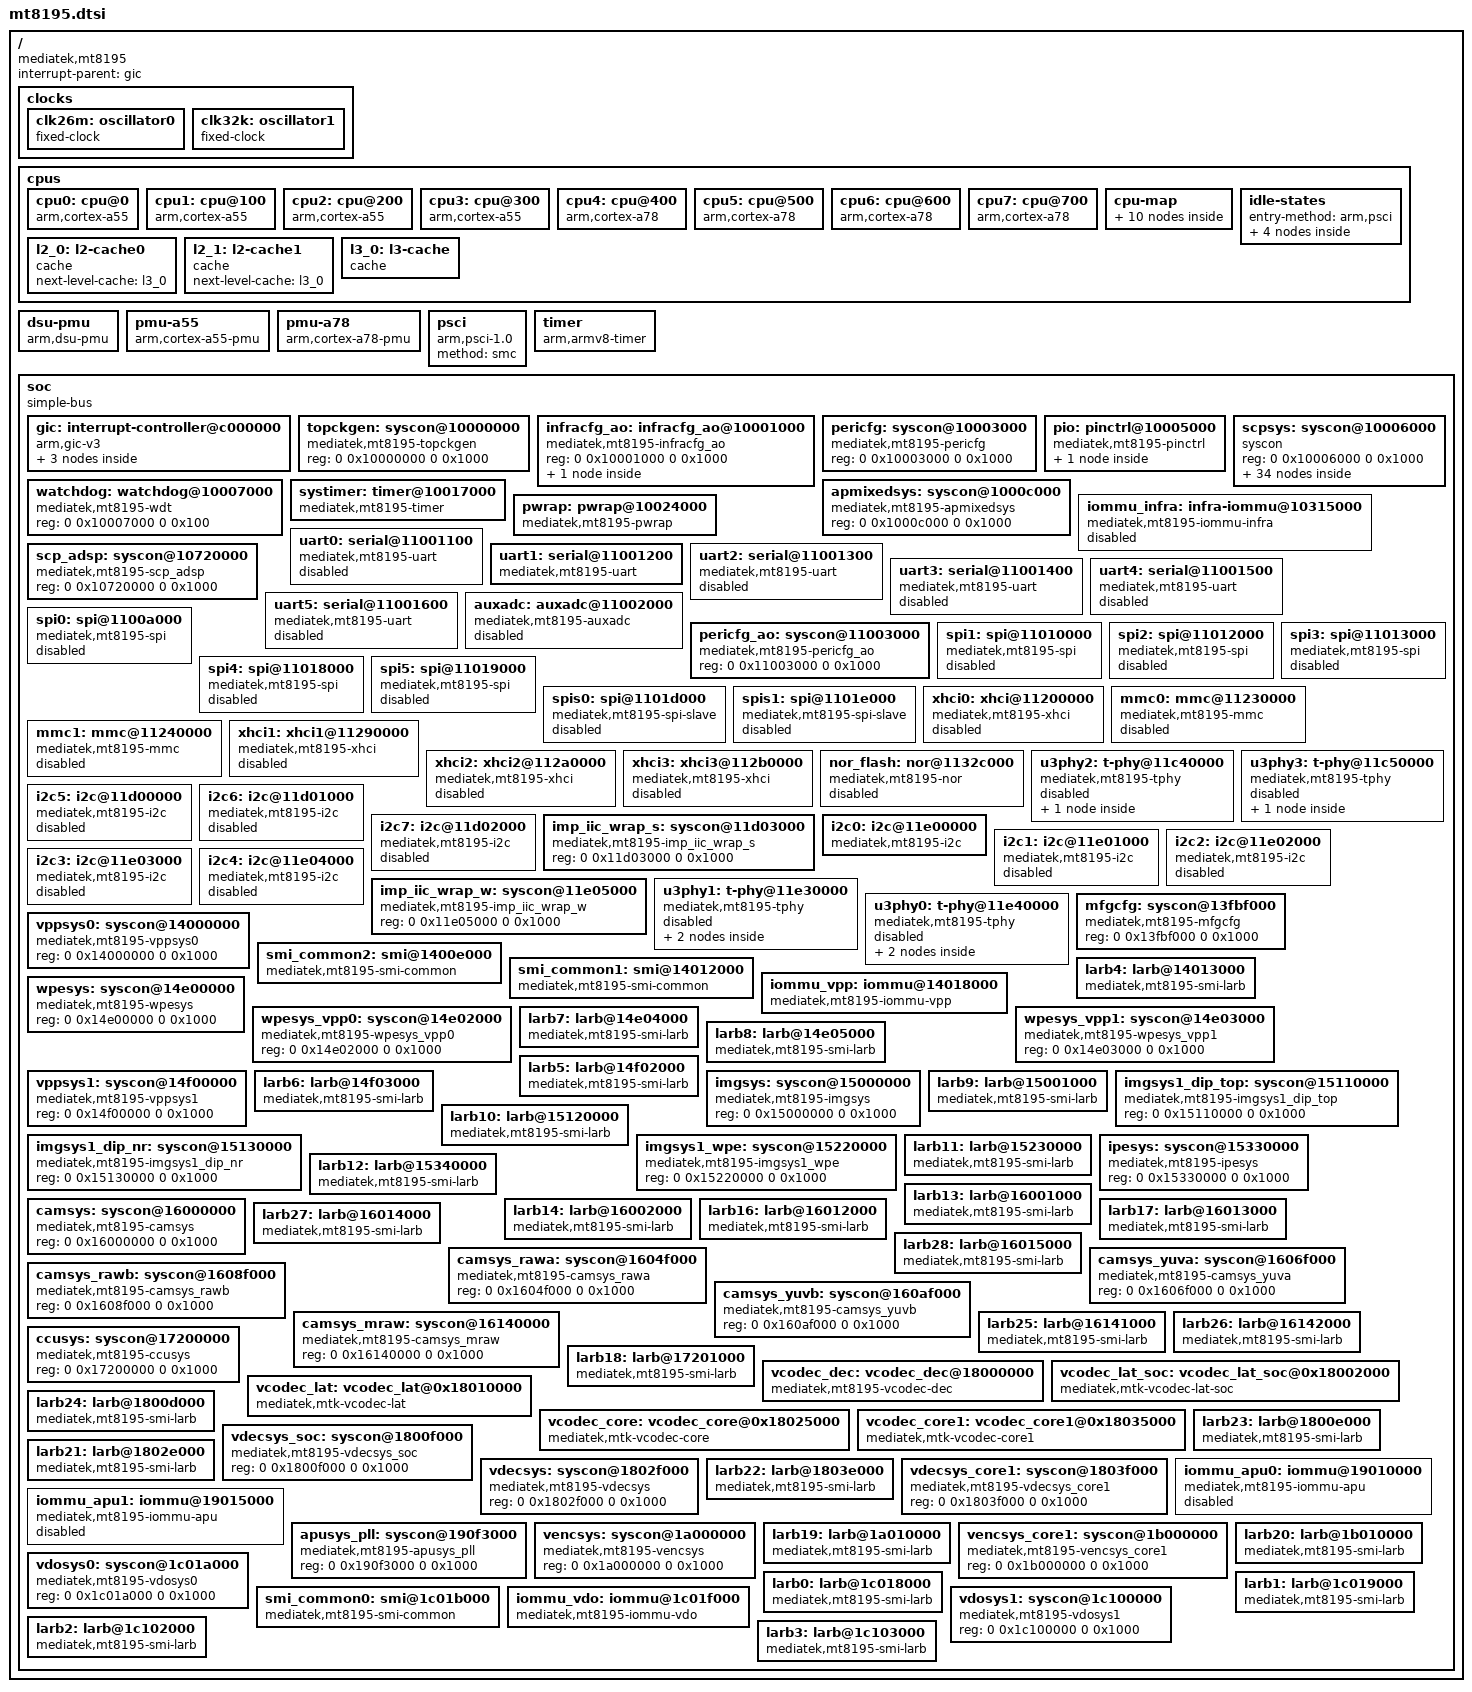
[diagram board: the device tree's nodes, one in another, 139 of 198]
// SPDX-License-Identifier: (GPL-2.0 OR MIT)
/*
 * Copyright (c) 2021 MediaTek Inc.
 * Author: Seiya Wang <seiya.wang@mediatek.com>
 */

/dts-v1/;

#include <dt-bindings/clock/mt8195-clk.h>
#include <dt-bindings/interrupt-controller/arm-gic.h>
#include <dt-bindings/interrupt-controller/irq.h>
#include <dt-bindings/memory/mt8195-memory-port.h>
#include <dt-bindings/phy/phy.h>
#include <dt-bindings/pinctrl/mt8195-pinfunc.h>
#include <dt-bindings/power/mt8195-power.h>
#include <dt-bindings/reset/ti-syscon.h>

/ {
	compatible = "mediatek,mt8195";
	interrupt-parent = <&gic>;
	#address-cells = <2>;
	#size-cells = <2>;

	clocks {
		clk26m: oscillator0 {
			compatible = "fixed-clock";
			#clock-cells = <0>;
			clock-frequency = <26000000>;
			clock-output-names = "clk26m";
		};

		clk32k: oscillator1 {
			compatible = "fixed-clock";
			#clock-cells = <0>;
			clock-frequency = <32768>;
			clock-output-names = "clk32k";
		};
	};

	cpus {
		#address-cells = <1>;
		#size-cells = <0>;

		cpu0: cpu@0 {
			device_type = "cpu";
			compatible = "arm,cortex-a55", "arm,armv8";
			reg = <0x000>;
			enable-method = "psci";
			clock-frequency = <1701000000>;
			capacity-dmips-mhz = <578>;
			cpu-idle-states = <&cpuoff_l &clusteroff_l>;
			next-level-cache = <&l2_0>;
			#cooling-cells = <2>;
		};

		cpu1: cpu@100 {
			device_type = "cpu";
			compatible = "arm,cortex-a55", "arm,armv8";
			reg = <0x100>;
			enable-method = "psci";
			clock-frequency = <1701000000>;
			capacity-dmips-mhz = <578>;
			cpu-idle-states = <&cpuoff_l &clusteroff_l>;
			next-level-cache = <&l2_0>;
			#cooling-cells = <2>;
		};

		cpu2: cpu@200 {
			device_type = "cpu";
			compatible = "arm,cortex-a55", "arm,armv8";
			reg = <0x200>;
			enable-method = "psci";
			clock-frequency = <1701000000>;
			capacity-dmips-mhz = <578>;
			cpu-idle-states = <&cpuoff_l &clusteroff_l>;
			next-level-cache = <&l2_0>;
			#cooling-cells = <2>;
		};

		cpu3: cpu@300 {
			device_type = "cpu";
			compatible = "arm,cortex-a55", "arm,armv8";
			reg = <0x300>;
			enable-method = "psci";
			clock-frequency = <1701000000>;
			capacity-dmips-mhz = <578>;
			cpu-idle-states = <&cpuoff_l &clusteroff_l>;
			next-level-cache = <&l2_0>;
			#cooling-cells = <2>;
		};

		cpu4: cpu@400 {
			device_type = "cpu";
			compatible = "arm,cortex-a78", "arm,armv8";
			reg = <0x400>;
			enable-method = "psci";
			clock-frequency = <2171000000>;
			capacity-dmips-mhz = <1024>;
			cpu-idle-states = <&cpuoff_b &clusteroff_b>;
			next-level-cache = <&l2_1>;
			#cooling-cells = <2>;
		};

		cpu5: cpu@500 {
			device_type = "cpu";
			compatible = "arm,cortex-a78", "arm,armv8";
			reg = <0x500>;
			enable-method = "psci";
			clock-frequency = <2171000000>;
			capacity-dmips-mhz = <1024>;
			cpu-idle-states = <&cpuoff_b &clusteroff_b>;
			next-level-cache = <&l2_1>;
			#cooling-cells = <2>;
		};

		cpu6: cpu@600 {
			device_type = "cpu";
			compatible = "arm,cortex-a78", "arm,armv8";
			reg = <0x600>;
			enable-method = "psci";
			clock-frequency = <2171000000>;
			capacity-dmips-mhz = <1024>;
			cpu-idle-states = <&cpuoff_b &clusteroff_b>;
			next-level-cache = <&l2_1>;
			#cooling-cells = <2>;
		};

		cpu7: cpu@700 {
			device_type = "cpu";
			compatible = "arm,cortex-a78", "arm,armv8";
			reg = <0x700>;
			enable-method = "psci";
			clock-frequency = <2171000000>;
			capacity-dmips-mhz = <1024>;
			cpu-idle-states = <&cpuoff_b &clusteroff_b>;
			next-level-cache = <&l2_1>;
			#cooling-cells = <2>;
		};

		cpu-map {
			cluster0 {
				core0 {
					cpu = <&cpu0>;
				};
				core1 {
					cpu = <&cpu1>;
				};
				core2 {
					cpu = <&cpu2>;
				};
				core3 {
					cpu = <&cpu3>;
				};
			};
			cluster1 {
				core0 {
					cpu = <&cpu4>;
				};
				core1 {
					cpu = <&cpu5>;
				};
				core2 {
					cpu = <&cpu6>;
				};
				core3 {
					cpu = <&cpu7>;
				};
			};
		};

		idle-states {
			entry-method = "arm,psci";
			cpuoff_l: cpuoff_l {
				compatible = "arm,idle-state";
				arm,psci-suspend-param = <0x00010001>;
				local-timer-stop;
				entry-latency-us = <50>;
				exit-latency-us = <95>;
				min-residency-us = <580>;
			};
			cpuoff_b: cpuoff_b {
				compatible = "arm,idle-state";
				arm,psci-suspend-param = <0x00010001>;
				local-timer-stop;
				entry-latency-us = <45>;
				exit-latency-us = <140>;
				min-residency-us = <740>;
			};
			clusteroff_l: clusteroff_l {
				compatible = "arm,idle-state";
				arm,psci-suspend-param = <0x01010002>;
				local-timer-stop;
				entry-latency-us = <55>;
				exit-latency-us = <155>;
				min-residency-us = <840>;
			};
			clusteroff_b: clusteroff_b {
				compatible = "arm,idle-state";
				arm,psci-suspend-param = <0x01010002>;
				local-timer-stop;
				entry-latency-us = <50>;
				exit-latency-us = <200>;
				min-residency-us = <1000>;
			};
		};

		l2_0: l2-cache0 {
			compatible = "cache";
			next-level-cache = <&l3_0>;
		};

		l2_1: l2-cache1 {
			compatible = "cache";
			next-level-cache = <&l3_0>;
		};

		l3_0: l3-cache {
			compatible = "cache";
		};
	};

	dsu-pmu {
		compatible = "arm,dsu-pmu";
		interrupts = <GIC_SPI 18 IRQ_TYPE_LEVEL_HIGH 0>;
		cpus = <&cpu0>, <&cpu1>, <&cpu2>, <&cpu3>,
		       <&cpu4>, <&cpu5>, <&cpu6>, <&cpu7>;
	};

	pmu-a55 {
		compatible = "arm,cortex-a55-pmu";
		interrupt-parent = <&gic>;
		interrupts = <GIC_PPI 7 IRQ_TYPE_LEVEL_HIGH &ppi_cluster0>;
	};

	pmu-a78 {
		compatible = "arm,cortex-a78-pmu";
		interrupt-parent = <&gic>;
		interrupts = <GIC_PPI 7 IRQ_TYPE_LEVEL_HIGH &ppi_cluster1>;
	};

	psci {
		compatible = "arm,psci-1.0";
		method = "smc";
	};

	timer: timer {
		compatible = "arm,armv8-timer";
		interrupt-parent = <&gic>;
		interrupts = <GIC_PPI 13 IRQ_TYPE_LEVEL_HIGH 0>,
			     <GIC_PPI 14 IRQ_TYPE_LEVEL_HIGH 0>,
			     <GIC_PPI 11 IRQ_TYPE_LEVEL_HIGH 0>,
			     <GIC_PPI 10 IRQ_TYPE_LEVEL_HIGH 0>;
		clock-frequency = <13000000>;
	};

	soc {
		#address-cells = <2>;
		#size-cells = <2>;
		compatible = "simple-bus";
		ranges;

		gic: interrupt-controller@c000000 {
			compatible = "arm,gic-v3";
			#interrupt-cells = <4>;
			#redistributor-regions = <1>;
			interrupt-parent = <&gic>;
			interrupt-controller;
			reg = <0 0x0c000000 0 0x40000>,
			      <0 0x0c040000 0 0x200000>;
			interrupts = <GIC_PPI 9 IRQ_TYPE_LEVEL_HIGH 0>;

			ppi-partitions {
				ppi_cluster0: interrupt-partition-0 {
					affinity = <&cpu0 &cpu1 &cpu2 &cpu3>;
				};
				ppi_cluster1: interrupt-partition-1 {
					affinity = <&cpu4 &cpu5 &cpu6 &cpu7>;
				};
			};
		};

		topckgen: syscon@10000000 {
			compatible = "mediatek,mt8195-topckgen", "syscon";
			reg = <0 0x10000000 0 0x1000>;
			#clock-cells = <1>;
		};

		infracfg_ao: infracfg_ao@10001000 {
			compatible = "mediatek,mt8195-infracfg_ao", "syscon", "simple-mfd";
			reg = <0 0x10001000 0 0x1000>;
			#clock-cells = <1>;
			infracfg_rst: reset-controller {
				compatible = "ti,syscon-reset";
				#reset-cells = <1>;
				ti,reset-bits = <
					0x140 18 0x144 18 0 0 (ASSERT_SET | DEASSERT_SET | STATUS_NONE)
					0x120 1 0x124 1 0 0   (ASSERT_SET | DEASSERT_SET | STATUS_NONE)
					0x730 1 0x734 1 0 0   (ASSERT_SET | DEASSERT_SET | STATUS_NONE)
					0x150 5 0x154 5 0 0   (ASSERT_SET | DEASSERT_SET | STATUS_NONE)
				>;
			};
		};

		pericfg: syscon@10003000 {
			compatible = "mediatek,mt8195-pericfg", "syscon";
			reg = <0 0x10003000 0 0x1000>;
			#clock-cells = <1>;
		};

		pio: pinctrl@10005000 {
			compatible = "mediatek,mt8195-pinctrl";
			reg = <0 0x10005000 0 0x1000>,
			      <0 0x11d10000 0 0x1000>,
			      <0 0x11d30000 0 0x1000>,
			      <0 0x11d40000 0 0x1000>,
			      <0 0x11e20000 0 0x1000>,
			      <0 0x11eb0000 0 0x1000>,
			      <0 0x11f40000 0 0x1000>,
			      <0 0x1000b000 0 0x1000>;
			reg-names = "iocfg0", "iocfg_bm", "iocfg_bl",
				    "iocfg_br", "iocfg_lm", "iocfg_rb",
				    "iocfg_tl", "eint";
			gpio-controller;
			#gpio-cells = <2>;
			gpio-ranges = <&pio 0 0 144>;
			interrupt-controller;
			interrupts = <GIC_SPI 212 IRQ_TYPE_LEVEL_HIGH 0>;
			#interrupt-cells = <2>;

			pmif_pin: pmif_default_pin {
				pinmux = <PINMUX_GPIO36__FUNC_RTC32K_CK>,
					 <PINMUX_GPIO40__FUNC_PWRAP_SPI0_CSN>,
					 <PINMUX_GPIO41__FUNC_PWRAP_SPI0_CK>,
					 <PINMUX_GPIO42__FUNC_PWRAP_SPI0_MO>,
					 <PINMUX_GPIO43__FUNC_PWRAP_SPI0_MI>,
					 <PINMUX_GPIO44__FUNC_SPMI_M_SCL>,
					 <PINMUX_GPIO45__FUNC_SPMI_M_SDA>;
			};
		};

		scpsys: syscon@10006000 {
			compatible = "syscon", "simple-mfd";
			reg = <0 0x10006000 0 0x1000>;
			#power-domain-cells = <1>;

			/* System Power Manager */
			spm: power-controller {
				compatible = "mediatek,mt8195-power-controller";
				#address-cells = <1>;
				#size-cells = <0>;
				#power-domain-cells = <1>;

				/* power domain of the SoC */
				power-domain@MT8195_POWER_DOMAIN_PCIE_MAC_P0 {
					reg = <MT8195_POWER_DOMAIN_PCIE_MAC_P0>;
					mediatek,infracfg = <&infracfg_ao>;
					#power-domain-cells = <0>;
				};

				power-domain@MT8195_POWER_DOMAIN_PCIE_MAC_P1 {
					reg = <MT8195_POWER_DOMAIN_PCIE_MAC_P1>;
					mediatek,infracfg = <&infracfg_ao>;
					#power-domain-cells = <0>;
				};

				power-domain@MT8195_POWER_DOMAIN_PCIE_PHY {
					reg = <MT8195_POWER_DOMAIN_PCIE_PHY>;
					#power-domain-cells = <0>;
				};

				power-domain@MT8195_POWER_DOMAIN_SSUSB_PCIE_PHY {
					reg = <MT8195_POWER_DOMAIN_SSUSB_PCIE_PHY>;
					#power-domain-cells = <0>;
				};

				power-domain@MT8195_POWER_DOMAIN_CSI_RX_TOP {
					reg = <MT8195_POWER_DOMAIN_CSI_RX_TOP>;
					clocks = <&topckgen CLK_TOP_SENINF>,
						 <&topckgen CLK_TOP_SENINF2>;
					clock-names = "csi_rx_top", "csi_rx_top1";
					#power-domain-cells = <0>;
				};

				power-domain@MT8195_POWER_DOMAIN_ETHER {
					reg = <MT8195_POWER_DOMAIN_ETHER>;
					clocks = <&pericfg_ao CLK_PERI_AO_ETHERNET_MAC>;
					clock-names = "ether";
					#power-domain-cells = <0>;
				};
#if 0
				power-domain@MT8195_POWER_DOMAIN_ADSP {
					reg = <MT8195_POWER_DOMAIN_ADSP>;
					clocks = <&topckgen CLK_TOP_ADSP>,
						 <&topckgen CLK_TOP_AUDIO_LOCAL_BUS>;
					clock-names = "adsp", "bus";
					#address-cells = <1>;
					#size-cells = <0>;
					#power-domain-cells = <1>;

					power-domain@MT8195_POWER_DOMAIN_AUDIO {
						reg = <MT8195_POWER_DOMAIN_AUDIO>;
						clocks = <&topckgen CLK_TOP_A1SYS_HP>,
							 <&topckgen CLK_TOP_AUD_INTBUS>,
							 <&topckgen CLK_TOP_AUDIO_LOCAL_BUS>,
							 <&infracfg_ao CLK_INFRA_AO_AUDIO_26M_B>;
						clock-names = "audio", "int_bus", "bus", "ao";
						mediatek,infracfg = <&infracfg_ao>;
						#power-domain-cells = <0>;
					};
				};

				/*power-domain@MT8195_POWER_DOMAIN_AUDIO_ASRC {
					reg = <MT8195_POWER_DOMAIN_AUDIO_ASRC>;
					clocks = <&topckgen CLK_TOP_AUDIO_LOCAL_BUS_SEL>,
						 <&topckgen CLK_TOP_ASM_L_SEL>,
						 <&infracfg_ao CLK_INFRA_AO_AUDIO_26M_B>;
					clock-names = "audio_asrc", "audio_asrc1", "audio_asrc2";
					mediatek,infracfg = <&infracfg_ao>;
					#power-domain-cells = <0>;
				};*/

				/*power-domain@MT8195_POWER_DOMAIN_NNA {
					reg = <MT8195_POWER_DOMAIN_NNA>;
					clocks = <&topckgen CLK_TOP_NNA0_SEL>;
					clock-names = "nna";
					mediatek,infracfg = <&infracfg_ao>;
					#address-cells = <1>;
					#size-cells = <0>;
					#power-domain-cells = <1>;

					power-domain@MT8195_POWER_DOMAIN_NNA0 {
						reg = <MT8195_POWER_DOMAIN_NNA0>;
						mediatek,infracfg = <&infracfg_ao>;
						#power-domain-cells = <0>;
					};

					power-domain@MT8195_POWER_DOMAIN_NNA1 {
						reg = <MT8195_POWER_DOMAIN_NNA1>;
						mediatek,infracfg = <&infracfg_ao>;
						#power-domain-cells = <0>;
					};
				};*/
#endif
				power-domain@MT8195_POWER_DOMAIN_MFG0 {
					reg = <MT8195_POWER_DOMAIN_MFG0>;
					#address-cells = <1>;
					#size-cells = <0>;
					#power-domain-cells = <1>;

					power-domain@MT8195_POWER_DOMAIN_MFG1 {
						reg = <MT8195_POWER_DOMAIN_MFG1>;
						clocks = <&apmixedsys CLK_APMIXED_MFGPLL>;
						clock-names = "mfg";
						mediatek,infracfg = <&infracfg_ao>;
						#address-cells = <1>;
						#size-cells = <0>;
						#power-domain-cells = <1>;

						power-domain@MT8195_POWER_DOMAIN_MFG2 {
							reg = <MT8195_POWER_DOMAIN_MFG2>;
							#power-domain-cells = <0>;
						};

						power-domain@MT8195_POWER_DOMAIN_MFG3 {
							reg = <MT8195_POWER_DOMAIN_MFG3>;
							#power-domain-cells = <0>;
						};

						power-domain@MT8195_POWER_DOMAIN_MFG4 {
							reg = <MT8195_POWER_DOMAIN_MFG4>;
							#power-domain-cells = <0>;
						};

						power-domain@MT8195_POWER_DOMAIN_MFG5 {
							reg = <MT8195_POWER_DOMAIN_MFG5>;
							#power-domain-cells = <0>;
						};

						power-domain@MT8195_POWER_DOMAIN_MFG6 {
							reg = <MT8195_POWER_DOMAIN_MFG6>;
							#power-domain-cells = <0>;
						};
					};
				};

				power-domain@MT8195_POWER_DOMAIN_VPPSYS0 {
					reg = <MT8195_POWER_DOMAIN_VPPSYS0>;
					clocks = <&topckgen CLK_TOP_VPP>,
						 <&topckgen CLK_TOP_CAM>,
						 <&topckgen CLK_TOP_CCU>,
						 <&topckgen CLK_TOP_IMG>,
						 <&topckgen CLK_TOP_VENC>,
						 <&topckgen CLK_TOP_VDEC>,
						 <&topckgen CLK_TOP_WPE_VPP>,
						 <&topckgen CLK_TOP_CFG_VPP0>,
						 <&vppsys0 CLK_VPP0_SMI_COMMON>,
						 <&vppsys0 CLK_VPP0_GALS_VDO0_LARB0>,
						 <&vppsys0 CLK_VPP0_GALS_VDO0_LARB1>,
						 <&vppsys0 CLK_VPP0_GALS_VENCSYS>,
						 <&vppsys0 CLK_VPP0_GALS_VENCSYS_CORE1>,
						 <&vppsys0 CLK_VPP0_GALS_INFRA>,
						 <&vppsys0 CLK_VPP0_GALS_CAMSYS>,
						 <&vppsys0 CLK_VPP0_GALS_VPP1_LARB5>,
						 <&vppsys0 CLK_VPP0_GALS_VPP1_LARB6>,
						 <&vppsys0 CLK_VPP0_SMI_REORDER>,
						 <&vppsys0 CLK_VPP0_SMI_IOMMU>,
						 <&vppsys0 CLK_VPP0_GALS_IMGSYS_CAMSYS>,
						 <&vppsys0 CLK_VPP0_GALS_EMI0_EMI1>,
						 <&vppsys0 CLK_VPP0_SMI_SUB_COMMON_REORDER>,
						 <&vppsys0 CLK_VPP0_SMI_RSI>,
						 <&vppsys0 CLK_VPP0_SMI_COMMON_LARB4>,
						 <&vppsys0 CLK_VPP0_GALS_VDEC_VDEC_CORE1>,
						 <&vppsys0 CLK_VPP0_GALS_VPP1_WPE>,
						 <&vppsys0 CLK_VPP0_GALS_VDO0_VDO1_VENCSYS_CORE1>;
					clock-names = "vppsys", "vppsys1", "vppsys2", "vppsys3",
						      "vppsys4", "vppsys5", "vppsys6", "vppsys7",
						      "vppsys0-0", "vppsys0-1", "vppsys0-2", "vppsys0-3",
						      "vppsys0-4", "vppsys0-5", "vppsys0-6", "vppsys0-7",
						      "vppsys0-8", "vppsys0-9", "vppsys0-10", "vppsys0-11",
						      "vppsys0-12", "vppsys0-13", "vppsys0-14",
						      "vppsys0-15", "vppsys0-16", "vppsys0-17",
						      "vppsys0-18";
					mediatek,infracfg = <&infracfg_ao>;
					#address-cells = <1>;
					#size-cells = <0>;
					#power-domain-cells = <1>;

					power-domain@MT8195_POWER_DOMAIN_VDEC1 {
						reg = <MT8195_POWER_DOMAIN_VDEC1>;
						clocks = <&vdecsys CLK_VDEC_LARB1>;
						clock-names = "vdec1-0";
						mediatek,infracfg = <&infracfg_ao>;
						#power-domain-cells = <0>;
					};

					power-domain@MT8195_POWER_DOMAIN_VENC_CORE1 {
						reg = <MT8195_POWER_DOMAIN_VENC_CORE1>;
						mediatek,infracfg = <&infracfg_ao>;
						#power-domain-cells = <0>;
					};

					power-domain@MT8195_POWER_DOMAIN_VDOSYS0 {
						reg = <MT8195_POWER_DOMAIN_VDOSYS0>;
						clocks = <&topckgen CLK_TOP_CFG_VDO0>,
							 <&vdosys0 CLK_VDO0_SMI_GALS>,
							 <&vdosys0 CLK_VDO0_SMI_COMMON>,
							 <&vdosys0 CLK_VDO0_SMI_EMI>,
							 <&vdosys0 CLK_VDO0_SMI_IOMMU>,
							 <&vdosys0 CLK_VDO0_SMI_LARB>,
							 <&vdosys0 CLK_VDO0_SMI_RSI>;
						clock-names = "vdosys0", "vdosys0-0", "vdosys0-1",
							      "vdosys0-2", "vdosys0-3",
							      "vdosys0-4", "vdosys0-5";
						mediatek,infracfg = <&infracfg_ao>;
						#address-cells = <1>;
						#size-cells = <0>;
						#power-domain-cells = <1>;

						power-domain@MT8195_POWER_DOMAIN_VPPSYS1 {
							reg = <MT8195_POWER_DOMAIN_VPPSYS1>;
							clocks = <&topckgen CLK_TOP_CFG_VPP1>,
								 <&vppsys1 CLK_VPP1_VPPSYS1_GALS>,
								 <&vppsys1 CLK_VPP1_VPPSYS1_LARB>;
							clock-names = "vppsys1", "vppsys1-0",
								      "vppsys1-1";
							mediatek,infracfg = <&infracfg_ao>;
							#power-domain-cells = <0>;
						};

						power-domain@MT8195_POWER_DOMAIN_WPESYS {
							reg = <MT8195_POWER_DOMAIN_WPESYS>;
							clocks = <&wpesys CLK_WPE_SMI_LARB7>,
								 <&wpesys CLK_WPE_SMI_LARB8>,
								 <&wpesys CLK_WPE_SMI_LARB7_P>,
								 <&wpesys CLK_WPE_SMI_LARB8_P>;
							clock-names = "wepsys-0", "wepsys-1", "wepsys-2",
								      "wepsys-3";
							mediatek,infracfg = <&infracfg_ao>;
							#power-domain-cells = <0>;
						};

						power-domain@MT8195_POWER_DOMAIN_VDEC0 {
							reg = <MT8195_POWER_DOMAIN_VDEC0>;
							clocks = <&vdecsys_soc CLK_VDEC_SOC_LARB1>;
							clock-names = "vdec0-0";
							mediatek,infracfg = <&infracfg_ao>;
							#power-domain-cells = <0>;
						};

						power-domain@MT8195_POWER_DOMAIN_VDEC2 {
							reg = <MT8195_POWER_DOMAIN_VDEC2>;
							clocks = <&vdecsys_core1 CLK_VDEC_CORE1_LARB1>;
							clock-names = "vdec2-0";
							mediatek,infracfg = <&infracfg_ao>;
							#power-domain-cells = <0>;
						};

						power-domain@MT8195_POWER_DOMAIN_VENC {
							reg = <MT8195_POWER_DOMAIN_VENC>;
							mediatek,infracfg = <&infracfg_ao>;
							#power-domain-cells = <0>;
						};

						power-domain@MT8195_POWER_DOMAIN_VDOSYS1 {
							reg = <MT8195_POWER_DOMAIN_VDOSYS1>;
							clocks = <&topckgen CLK_TOP_CFG_VDO1>,
								 <&vdosys1 CLK_VDO1_SMI_LARB2>,
								 <&vdosys1 CLK_VDO1_SMI_LARB3>,
								 <&vdosys1 CLK_VDO1_GALS>;
							clock-names = "vdosys1", "vdosys1-0",
								      "vdosys1-1", "vdosys1-2";
							mediatek,infracfg = <&infracfg_ao>;
							#address-cells = <1>;
							#size-cells = <0>;
							#power-domain-cells = <1>;

							power-domain@MT8195_POWER_DOMAIN_DP_TX {
								reg = <MT8195_POWER_DOMAIN_DP_TX>;
								mediatek,infracfg = <&infracfg_ao>;
								#power-domain-cells = <0>;
							};

							power-domain@MT8195_POWER_DOMAIN_EPD_TX {
								reg = <MT8195_POWER_DOMAIN_EPD_TX>;
								mediatek,infracfg = <&infracfg_ao>;
								#power-domain-cells = <0>;
							};

							power-domain@MT8195_POWER_DOMAIN_HDMI_TX {
								reg = <MT8195_POWER_DOMAIN_HDMI_TX>;
								clocks = <&topckgen CLK_TOP_HDMI_APB>;
								clock-names = "hdmi_tx";
								#power-domain-cells = <0>;
							};
						};

						power-domain@MT8195_POWER_DOMAIN_IMG {
							reg = <MT8195_POWER_DOMAIN_IMG>;
							clocks = <&imgsys CLK_IMG_LARB9>,
								 <&imgsys CLK_IMG_GALS>;
							clock-names = "img-0", "img-1";
							mediatek,infracfg = <&infracfg_ao>;
							#address-cells = <1>;
							#size-cells = <0>;
							#power-domain-cells = <1>;

							power-domain@MT8195_POWER_DOMAIN_DIP {
								reg = <MT8195_POWER_DOMAIN_DIP>;
								#power-domain-cells = <0>;
							};

							power-domain@MT8195_POWER_DOMAIN_IPE {
								reg = <MT8195_POWER_DOMAIN_IPE>;
								clocks = <&topckgen CLK_TOP_IPE>,
									 <&imgsys CLK_IMG_IPE>,
									 <&ipesys CLK_IPE_SMI_LARB12>;
								clock-names = "ipe", "ipe-0", "ipe-1";
								mediatek,infracfg = <&infracfg_ao>;
								#power-domain-cells = <0>;
							};
						};

						power-domain@MT8195_POWER_DOMAIN_CAM {
							reg = <MT8195_POWER_DOMAIN_CAM>;
							clocks = <&camsys CLK_CAM_LARB13>,
								 <&camsys CLK_CAM_LARB14>,
								 <&camsys CLK_CAM_CAM2MM0_GALS>,
								 <&camsys CLK_CAM_CAM2MM1_GALS>,
								 <&camsys CLK_CAM_CAM2SYS_GALS>;
							clock-names = "cam-0", "cam-1", "cam-2", "cam-3",
								      "cam-4";
							mediatek,infracfg = <&infracfg_ao>;
							#address-cells = <1>;
							#size-cells = <0>;
							#power-domain-cells = <1>;

							power-domain@MT8195_POWER_DOMAIN_CAM_RAWA {
								reg = <MT8195_POWER_DOMAIN_CAM_RAWA>;
								#power-domain-cells = <0>;
							};

							power-domain@MT8195_POWER_DOMAIN_CAM_RAWB {
								reg = <MT8195_POWER_DOMAIN_CAM_RAWB>;
								#power-domain-cells = <0>;
							};

							power-domain@MT8195_POWER_DOMAIN_CAM_MRAW {
								reg = <MT8195_POWER_DOMAIN_CAM_MRAW>;
								#power-domain-cells = <0>;
							};
						};
					};
				};
			};
		};

		watchdog: watchdog@10007000 {
			compatible = "mediatek,mt8195-wdt",
				     "mediatek,mt6589-wdt";
			reg = <0 0x10007000 0 0x100>;
		};

		apmixedsys: syscon@1000c000 {
			compatible = "mediatek,mt8195-apmixedsys", "syscon";
			reg = <0 0x1000c000 0 0x1000>;
			#clock-cells = <1>;
		};

		systimer: timer@10017000 {
			compatible = "mediatek,mt8195-timer",
				     "mediatek,mt6765-timer";
			reg = <0 0x10017000 0 0x1000>;
			interrupts = <GIC_SPI 265 IRQ_TYPE_LEVEL_HIGH 0>;
			clocks = <&topckgen CLK_TOP_CLK26M_D2>;
		};

		pwrap: pwrap@10024000 {
			compatible = "mediatek,mt8195-pwrap", "syscon";
			reg = <0 0x10024000 0 0x1000>;
			reg-names = "pwrap";
			interrupts = <GIC_SPI 243 IRQ_TYPE_LEVEL_HIGH 0>;
			clocks = <&infracfg_ao CLK_INFRA_AO_PMIC_AP>,
				 <&infracfg_ao CLK_INFRA_AO_PMIC_TMR>;
			clock-names = "spi", "wrap";
			assigned-clocks = <&topckgen CLK_TOP_PWRAP_ULPOSC>;
			assigned-clock-parents = <&topckgen CLK_TOP_ULPOSC1_D10>;
			pinctrl-names = "default";
			pinctrl-0 = <&pmif_pin>;
		};

		iommu_infra: infra-iommu@10315000 {
			compatible = "mediatek,mt8195-iommu-infra";
			reg = <0 0x10315000 0 0x1000>,
			      <0 0x11003000 0 0x1000>;
			interrupts = <GIC_SPI 795 IRQ_TYPE_LEVEL_HIGH 0>;
			clocks = <&clk26m>;
			clock-names = "bclk";
			#iommu-cells = <1>;
			status = "disabled";
		};

		scp_adsp: syscon@10720000 {
			compatible = "mediatek,mt8195-scp_adsp", "syscon";
			reg = <0 0x10720000 0 0x1000>;
			#clock-cells = <1>;
		};

		uart0: serial@11001100 {
			compatible = "mediatek,mt8195-uart",
				     "mediatek,mt6577-uart";
			reg = <0 0x11001100 0 0x100>;
			interrupts = <GIC_SPI 141 IRQ_TYPE_LEVEL_HIGH 0>;
			clocks = <&clk26m>, <&infracfg_ao CLK_INFRA_AO_UART0>;
			clock-names = "baud", "bus";
			status = "disabled";
		};

		uart1: serial@11001200 {
			compatible = "mediatek,mt8195-uart",
				     "mediatek,mt6577-uart";
			reg = <0 0x11001200 0 0x100>;
			interrupts = <GIC_SPI 142 IRQ_TYPE_LEVEL_HIGH 0>;
			clocks = <&clk26m>, <&infracfg_ao CLK_INFRA_AO_UART1>;
			clock-names = "baud", "bus";
		};

		uart2: serial@11001300 {
			compatible = "mediatek,mt8195-uart",
				     "mediatek,mt6577-uart";
			reg = <0 0x11001300 0 0x100>;
			interrupts = <GIC_SPI 143 IRQ_TYPE_LEVEL_HIGH 0>;
			clocks = <&clk26m>, <&infracfg_ao CLK_INFRA_AO_UART2>;
			clock-names = "baud", "bus";
			status = "disabled";
		};

		uart3: serial@11001400 {
			compatible = "mediatek,mt8195-uart",
				     "mediatek,mt6577-uart";
			reg = <0 0x11001400 0 0x100>;
			interrupts = <GIC_SPI 723 IRQ_TYPE_LEVEL_HIGH 0>;
			clocks = <&clk26m>, <&infracfg_ao CLK_INFRA_AO_UART3>;
			clock-names = "baud", "bus";
			status = "disabled";
		};

		uart4: serial@11001500 {
			compatible = "mediatek,mt8195-uart",
				     "mediatek,mt6577-uart";
			reg = <0 0x11001500 0 0x100>;
			interrupts = <GIC_SPI 724 IRQ_TYPE_LEVEL_HIGH 0>;
			clocks = <&clk26m>, <&infracfg_ao CLK_INFRA_AO_UART4>;
			clock-names = "baud", "bus";
			status = "disabled";
		};

		uart5: serial@11001600 {
			compatible = "mediatek,mt8195-uart",
				     "mediatek,mt6577-uart";
			reg = <0 0x11001600 0 0x100>;
			interrupts = <GIC_SPI 725 IRQ_TYPE_LEVEL_HIGH 0>;
			clocks = <&clk26m>, <&infracfg_ao CLK_INFRA_AO_UART5>;
			clock-names = "baud", "bus";
			status = "disabled";
		};

		auxadc: auxadc@11002000 {
			compatible = "mediatek,mt8195-auxadc",
				     "mediatek,mt8173-auxadc";
			reg = <0 0x11002000 0 0x1000>;
			clocks = <&infracfg_ao CLK_INFRA_AO_AUXADC>;
			clock-names = "main";
			#io-channel-cells = <1>;
			status = "disabled";
		};

		pericfg_ao: syscon@11003000 {
			compatible = "mediatek,mt8195-pericfg_ao", "syscon";
			reg = <0 0x11003000 0 0x1000>;
			#clock-cells = <1>;
		};

		spi0: spi@1100a000 {
			compatible = "mediatek,mt8195-spi",
				     "mediatek,mt6765-spi";
			reg = <0 0x1100a000 0 0x100>;
			interrupts = <GIC_SPI 191 IRQ_TYPE_LEVEL_HIGH 0>;
			clocks = <&topckgen CLK_TOP_UNIVPLL_D6_D2>,
				 <&topckgen CLK_TOP_SPI>,
				 <&infracfg_ao CLK_INFRA_AO_SPI0>;
			clock-names = "parent-clk", "sel-clk", "spi-clk";
			status = "disabled";
		};

		spi1: spi@11010000 {
			compatible = "mediatek,mt8195-spi",
				     "mediatek,mt6765-spi";
			reg = <0 0x11010000 0 0x100>;
			interrupts = <GIC_SPI 192 IRQ_TYPE_LEVEL_HIGH 0>;
			clocks = <&topckgen CLK_TOP_UNIVPLL_D6_D2>,
				 <&topckgen CLK_TOP_SPI>,
				 <&infracfg_ao CLK_INFRA_AO_SPI1>;
			clock-names = "parent-clk", "sel-clk", "spi-clk";
			status = "disabled";
		};

		spi2: spi@11012000 {
			compatible = "mediatek,mt8195-spi",
				     "mediatek,mt6765-spi";
			reg = <0 0x11012000 0 0x100>;
			interrupts = <GIC_SPI 193 IRQ_TYPE_LEVEL_HIGH 0>;
			clocks = <&topckgen CLK_TOP_UNIVPLL_D6_D2>,
				 <&topckgen CLK_TOP_SPI>,
				 <&infracfg_ao CLK_INFRA_AO_SPI2>;
			clock-names = "parent-clk", "sel-clk", "spi-clk";
			status = "disabled";
		};

		spi3: spi@11013000 {
			compatible = "mediatek,mt8195-spi",
				     "mediatek,mt6765-spi";
			reg = <0 0x11013000 0 0x100>;
			interrupts = <GIC_SPI 194 IRQ_TYPE_LEVEL_HIGH 0>;
			clocks = <&topckgen CLK_TOP_UNIVPLL_D6_D2>,
				 <&topckgen CLK_TOP_SPI>,
				 <&infracfg_ao CLK_INFRA_AO_SPI3>;
			clock-names = "parent-clk", "sel-clk", "spi-clk";
			status = "disabled";
		};

		spi4: spi@11018000 {
			compatible = "mediatek,mt8195-spi",
				     "mediatek,mt6765-spi";
			reg = <0 0x11018000 0 0x100>;
			interrupts = <GIC_SPI 195 IRQ_TYPE_LEVEL_HIGH 0>;
			clocks = <&topckgen CLK_TOP_UNIVPLL_D6_D2>,
				 <&topckgen CLK_TOP_SPI>,
				 <&infracfg_ao CLK_INFRA_AO_SPI4>;
			clock-names = "parent-clk", "sel-clk", "spi-clk";
			status = "disabled";
		};

		spi5: spi@11019000 {
			compatible = "mediatek,mt8195-spi",
				     "mediatek,mt6765-spi";
			reg = <0 0x11019000 0 0x100>;
			interrupts = <GIC_SPI 196 IRQ_TYPE_LEVEL_HIGH 0>;
			clocks = <&topckgen CLK_TOP_UNIVPLL_D6_D2>,
				 <&topckgen CLK_TOP_SPI>,
				 <&infracfg_ao CLK_INFRA_AO_SPI5>;
			clock-names = "parent-clk", "sel-clk", "spi-clk";
			status = "disabled";
		};

		spis0: spi@1101d000 {
			compatible = "mediatek,mt8195-spi-slave";
			reg = <0 0x1101d000 0 0x100>;
			interrupts = <GIC_SPI 197 IRQ_TYPE_LEVEL_HIGH 0>;
			clocks = <&infracfg_ao CLK_INFRA_AO_SPIS0>;
			clock-names = "spi";
			assigned-clocks = <&topckgen CLK_TOP_SPIS>;
			assigned-clock-parents = <&topckgen CLK_TOP_UNIVPLL_D6>;
			status = "disabled";
		};

		spis1: spi@1101e000 {
			compatible = "mediatek,mt8195-spi-slave";
			reg = <0 0x1101e000 0 0x100>;
			interrupts = <GIC_SPI 198 IRQ_TYPE_LEVEL_HIGH 0>;
			clocks = <&infracfg_ao CLK_INFRA_AO_SPIS1>;
			clock-names = "spi";
			assigned-clocks = <&topckgen CLK_TOP_SPIS>;
			assigned-clock-parents = <&topckgen CLK_TOP_UNIVPLL_D6>;
			status = "disabled";
		};

		xhci0: xhci@11200000 {
			compatible = "mediatek,mt8195-xhci",
				     "mediatek,mtk-xhci";
			reg = <0 0x11200000 0 0x1000>,
			      <0 0x11203e00 0 0x0100>;
			reg-names = "mac", "ippc";
			interrupts = <GIC_SPI 129 IRQ_TYPE_LEVEL_HIGH 0>;
			phys = <&u2port0 PHY_TYPE_USB2>,
			       <&u3port0 PHY_TYPE_USB3>;
			assigned-clocks = <&topckgen CLK_TOP_USB_TOP>,
					  <&topckgen CLK_TOP_SSUSB_XHCI>;
			assigned-clock-parents = <&topckgen CLK_TOP_UNIVPLL_D5_D4>,
						 <&topckgen CLK_TOP_UNIVPLL_D5_D4>;
			clocks = <&infracfg_ao CLK_INFRA_AO_SSUSB>,
				 <&infracfg_ao CLK_INFRA_AO_SSUSB_XHCI>,
				 <&topckgen CLK_TOP_SSUSB_REF>,
				 <&apmixedsys CLK_APMIXED_USB1PLL>;
			clock-names = "sys_ck", "xhci_ck", "ref_ck", "mcu_ck";
			mediatek,syscon-wakeup = <&pericfg 0x400 103>;
			wakeup-source;
			status = "disabled";
		};

		mmc0: mmc@11230000 {
			compatible = "mediatek,mt8195-mmc",
				     "mediatek,mt8192-mmc";
			reg = <0 0x11230000 0 0x10000>,
			      <0 0x11f50000 0 0x1000>;
			interrupts = <GIC_SPI 131 IRQ_TYPE_LEVEL_HIGH 0>;
			clocks = <&topckgen CLK_TOP_MSDC50_0>,
				 <&infracfg_ao CLK_INFRA_AO_MSDC0>,
				 <&infracfg_ao CLK_INFRA_AO_MSDC0_SRC>;
			clock-names = "source", "hclk", "source_cg";
			status = "disabled";
		};

		mmc1: mmc@11240000 {
			compatible = "mediatek,mt8195-mmc",
				     "mediatek,mt8192-mmc";
			reg = <0 0x11240000 0 0x1000>,
			      <0 0x11c70000 0 0x1000>;
			interrupts = <GIC_SPI 135 IRQ_TYPE_LEVEL_HIGH 0>;
			clocks = <&topckgen CLK_TOP_MSDC30_1>,
				 <&infracfg_ao CLK_INFRA_AO_MSDC1>,
				 <&infracfg_ao CLK_INFRA_AO_MSDC1_SRC>;
			clock-names = "source", "hclk", "source_cg";
			status = "disabled";
		};

		xhci1: xhci1@11290000 {
			compatible = "mediatek,mt8195-xhci",
				     "mediatek,mtk-xhci";
			reg = <0 0x11290000 0 0x1000>,
			      <0 0x11293e00 0 0x0100>;
			reg-names = "mac", "ippc";
			interrupts = <GIC_SPI 530 IRQ_TYPE_LEVEL_HIGH 0>;
			phys = <&u2port1 PHY_TYPE_USB2>;
			assigned-clocks = <&topckgen CLK_TOP_USB_TOP_1P>,
					  <&topckgen CLK_TOP_SSUSB_XHCI_1P>;
			assigned-clock-parents = <&topckgen CLK_TOP_UNIVPLL_D5_D4>,
						 <&topckgen CLK_TOP_UNIVPLL_D5_D4>;
			clocks = <&pericfg_ao CLK_PERI_AO_SSUSB_1P_BUS>,
				 <&pericfg_ao CLK_PERI_AO_SSUSB_1P_XHCI>,
				 <&topckgen CLK_TOP_SSUSB_P1_REF>,
				 <&apmixedsys CLK_APMIXED_USB1PLL>;
			clock-names = "sys_ck", "xhci_ck", "ref_ck", "mcu_ck";
			status = "disabled";
		};

		xhci2: xhci2@112a0000 {
			compatible = "mediatek,mt8195-xhci",
				     "mediatek,mtk-xhci";
			reg = <0 0x112a0000 0 0x1000>,
			      <0 0x112a3e00 0 0x0100>;
			reg-names = "mac", "ippc";
			interrupts = <GIC_SPI 533 IRQ_TYPE_LEVEL_HIGH 0>;
			phys = <&u2port2 PHY_TYPE_USB2>;
			assigned-clocks = <&topckgen CLK_TOP_USB_TOP_2P>,
					  <&topckgen CLK_TOP_SSUSB_XHCI_2P>;
			assigned-clock-parents = <&topckgen CLK_TOP_UNIVPLL_D5_D4>,
						 <&topckgen CLK_TOP_UNIVPLL_D5_D4>;
			clocks = <&pericfg_ao CLK_PERI_AO_SSUSB_2P_BUS>,
				 <&pericfg_ao CLK_PERI_AO_SSUSB_2P_XHCI>,
				 <&topckgen CLK_TOP_SSUSB_P2_REF>;
			clock-names = "sys_ck", "xhci_ck", "ref_ck";
			status = "disabled";
		};

		xhci3: xhci3@112b0000 {
			compatible = "mediatek,mt8195-xhci",
				     "mediatek,mtk-xhci";
			reg = <0 0x112b0000 0 0x1000>,
			      <0 0x112b3e00 0 0x0100>;
			reg-names = "mac", "ippc";
			interrupts = <GIC_SPI 536 IRQ_TYPE_LEVEL_HIGH 0>;
			phys = <&u2port3 PHY_TYPE_USB2>;
			assigned-clocks = <&topckgen CLK_TOP_USB_TOP_3P>,
					  <&topckgen CLK_TOP_SSUSB_XHCI_3P>;
			assigned-clock-parents = <&topckgen CLK_TOP_UNIVPLL_D5_D4>,
						 <&topckgen CLK_TOP_UNIVPLL_D5_D4>;
			clocks = <&pericfg_ao CLK_PERI_AO_SSUSB_3P_BUS>,
				 <&pericfg_ao CLK_PERI_AO_SSUSB_3P_XHCI>,
				 <&topckgen CLK_TOP_SSUSB_P3_REF>;
			clock-names = "sys_ck", "xhci_ck", "ref_ck";
			usb2-lpm-disable;
			status = "disabled";
		};

		nor_flash: nor@1132c000 {
			compatible = "mediatek,mt8195-nor",
				     "mediatek,mt8173-nor";
			reg = <0 0x1132c000 0 0x1000>;
			interrupts = <GIC_SPI 825 IRQ_TYPE_LEVEL_HIGH 0>;
			clocks = <&topckgen CLK_TOP_SPINOR>,
				 <&pericfg_ao CLK_PERI_AO_FLASHIF_FLASH>,
				 <&pericfg_ao CLK_PERI_AO_FLASHIF_BUS>;
			clock-names = "spi", "sf", "axi";
			#address-cells = <1>;
			#size-cells = <0>;
			status = "disabled";
		};

		u3phy2: t-phy@11c40000 {
			compatible = "mediatek,mt8195-tphy", "mediatek,generic-tphy-v2";
			#address-cells = <1>;
			#size-cells = <1>;
			ranges = <0 0 0x11c40000 0x700>;
			status = "disabled";

			u2port2: usb-phy@0 {
				reg = <0x0 0x700>;
				clocks = <&topckgen CLK_TOP_SSUSB_PHY_P2_REF>;
				clock-names = "ref";
				#phy-cells = <1>;
			};
		};

		u3phy3: t-phy@11c50000 {
			compatible = "mediatek,mt8195-tphy", "mediatek,generic-tphy-v2";
			#address-cells = <1>;
			#size-cells = <1>;
			ranges = <0 0 0x11c50000 0x700>;
			status = "disabled";

			u2port3: usb-phy@0 {
				reg = <0x0 0x700>;
				clocks = <&topckgen CLK_TOP_SSUSB_PHY_P3_REF>;
				clock-names = "ref";
				#phy-cells = <1>;
			};
		};

		i2c5: i2c@11d00000 {
			compatible = "mediatek,mt8195-i2c",
				     "mediatek,mt8192-i2c";
			reg = <0 0x11d00000 0 0x1000>,
			      <0 0x10220580 0 0x80>;
			interrupts = <GIC_SPI 154 IRQ_TYPE_LEVEL_HIGH 0>;
			clock-div = <1>;
			clocks = <&imp_iic_wrap_s CLK_IMP_IIC_WRAP_S_I2C5>,
				 <&infracfg_ao CLK_INFRA_AO_APDMA_B>;
			clock-names = "main", "dma";
			#address-cells = <1>;
			#size-cells = <0>;
			status = "disabled";
		};

		i2c6: i2c@11d01000 {
			compatible = "mediatek,mt8195-i2c",
				     "mediatek,mt8192-i2c";
			reg = <0 0x11d01000 0 0x1000>,
			      <0 0x10220600 0 0x80>;
			interrupts = <GIC_SPI 155 IRQ_TYPE_LEVEL_HIGH 0>;
			clock-div = <1>;
			clocks = <&imp_iic_wrap_s CLK_IMP_IIC_WRAP_S_I2C6>,
				 <&infracfg_ao CLK_INFRA_AO_APDMA_B>;
			clock-names = "main", "dma";
			#address-cells = <1>;
			#size-cells = <0>;
			status = "disabled";
		};

		i2c7: i2c@11d02000 {
			compatible = "mediatek,mt8195-i2c",
				     "mediatek,mt8192-i2c";
			reg = <0 0x11d02000 0 0x1000>,
			      <0 0x10220680 0 0x80>;
			interrupts = <GIC_SPI 156 IRQ_TYPE_LEVEL_HIGH 0>;
			clock-div = <1>;
			clocks = <&imp_iic_wrap_s CLK_IMP_IIC_WRAP_S_I2C7>,
				 <&infracfg_ao CLK_INFRA_AO_APDMA_B>;
			clock-names = "main", "dma";
			#address-cells = <1>;
			#size-cells = <0>;
			status = "disabled";
		};

		imp_iic_wrap_s: syscon@11d03000 {
			compatible = "mediatek,mt8195-imp_iic_wrap_s", "syscon";
			reg = <0 0x11d03000 0 0x1000>;
			#clock-cells = <1>;
		};

		i2c0: i2c@11e00000 {
			compatible = "mediatek,mt8195-i2c",
				     "mediatek,mt8192-i2c";
			reg = <0 0x11e00000 0 0x1000>,
			      <0 0x10220080 0 0x80>;
			interrupts = <GIC_SPI 144 IRQ_TYPE_LEVEL_HIGH 0>;
			clock-div = <1>;
			clocks = <&imp_iic_wrap_w CLK_IMP_IIC_WRAP_W_I2C0>,
				 <&infracfg_ao CLK_INFRA_AO_APDMA_B>;
			clock-names = "main", "dma";
			#address-cells = <1>;
			#size-cells = <0>;
			status = "okay";
		};

		i2c1: i2c@11e01000 {
			compatible = "mediatek,mt8195-i2c",
				     "mediatek,mt8192-i2c";
			reg = <0 0x11e01000 0 0x1000>,
			      <0 0x10220200 0 0x80>;
			interrupts = <GIC_SPI 147 IRQ_TYPE_LEVEL_HIGH 0>;
			clock-div = <1>;
			clocks = <&imp_iic_wrap_w CLK_IMP_IIC_WRAP_W_I2C1>,
				 <&infracfg_ao CLK_INFRA_AO_APDMA_B>;
			clock-names = "main", "dma";
			#address-cells = <1>;
			#size-cells = <0>;
			status = "disabled";
		};

		i2c2: i2c@11e02000 {
			compatible = "mediatek,mt8195-i2c",
				     "mediatek,mt8192-i2c";
			reg = <0 0x11e02000 0 0x1000>,
			      <0 0x10220380 0 0x80>;
			interrupts = <GIC_SPI 150 IRQ_TYPE_LEVEL_HIGH 0>;
			clock-div = <1>;
			clocks = <&imp_iic_wrap_w CLK_IMP_IIC_WRAP_W_I2C2>,
				 <&infracfg_ao CLK_INFRA_AO_APDMA_B>;
			clock-names = "main", "dma";
			#address-cells = <1>;
			#size-cells = <0>;
			status = "disabled";
		};

		i2c3: i2c@11e03000 {
			compatible = "mediatek,mt8195-i2c",
				     "mediatek,mt8192-i2c";
			reg = <0 0x11e03000 0 0x1000>,
			      <0 0x10220480 0 0x80>;
			interrupts = <GIC_SPI 152 IRQ_TYPE_LEVEL_HIGH 0>;
			clock-div = <1>;
			clocks = <&imp_iic_wrap_w CLK_IMP_IIC_WRAP_W_I2C3>,
				 <&infracfg_ao CLK_INFRA_AO_APDMA_B>;
			clock-names = "main", "dma";
			#address-cells = <1>;
			#size-cells = <0>;
			status = "disabled";
		};

		i2c4: i2c@11e04000 {
			compatible = "mediatek,mt8195-i2c",
				     "mediatek,mt8192-i2c";
			reg = <0 0x11e04000 0 0x1000>,
			      <0 0x10220500 0 0x80>;
			interrupts = <GIC_SPI 153 IRQ_TYPE_LEVEL_HIGH 0>;
			clock-div = <1>;
			clocks = <&imp_iic_wrap_w CLK_IMP_IIC_WRAP_W_I2C4>,
				 <&infracfg_ao CLK_INFRA_AO_APDMA_B>;
			clock-names = "main", "dma";
			#address-cells = <1>;
			#size-cells = <0>;
			status = "disabled";
		};

		imp_iic_wrap_w: syscon@11e05000 {
			compatible = "mediatek,mt8195-imp_iic_wrap_w", "syscon";
			reg = <0 0x11e05000 0 0x1000>;
			#clock-cells = <1>;
		};

		u3phy1: t-phy@11e30000 {
			compatible = "mediatek,mt8195-tphy", "mediatek,generic-tphy-v2";
			#address-cells = <1>;
			#size-cells = <1>;
			ranges = <0 0 0x11e30000 0xe00>;
			status = "disabled";

			u2port1: usb-phy@0 {
				reg = <0x0 0x700>;
				clocks = <&topckgen CLK_TOP_SSUSB_PHY_P1_REF>,
					 <&clk26m>;
				clock-names = "ref", "da_ref";
				#phy-cells = <1>;
			};

			u3port1: usb-phy@700 {
				reg = <0x700 0x700>;
				clocks = <&apmixedsys CLK_APMIXED_PLL_SSUSB26M>,
					 <&topckgen CLK_TOP_SSUSB_PHY_P1_REF>;
				clock-names = "ref", "da_ref";
				#phy-cells = <1>;
			};
		};

		u3phy0: t-phy@11e40000 {
			compatible = "mediatek,mt8195-tphy", "mediatek,generic-tphy-v2";
			#address-cells = <1>;
			#size-cells = <1>;
			ranges = <0 0 0x11e40000 0xe00>;
			status = "disabled";

			u2port0: usb-phy@0 {
				reg = <0x0 0x700>;
				clocks = <&topckgen CLK_TOP_SSUSB_PHY_REF>,
					 <&clk26m>;
				clock-names = "ref", "da_ref";
				#phy-cells = <1>;
			};

			u3port0: usb-phy@700 {
				reg = <0x700 0x700>;
				clocks = <&apmixedsys CLK_APMIXED_PLL_SSUSB26M>,
					 <&topckgen CLK_TOP_SSUSB_PHY_REF>;
				clock-names = "ref", "da_ref";
				#phy-cells = <1>;
			};
		};

		mfgcfg: syscon@13fbf000 {
			compatible = "mediatek,mt8195-mfgcfg", "syscon";
			reg = <0 0x13fbf000 0 0x1000>;
			#clock-cells = <1>;
		};

		vppsys0: syscon@14000000 {
			compatible = "mediatek,mt8195-vppsys0", "syscon";
			reg = <0 0x14000000 0 0x1000>;
			#clock-cells = <1>;
		};

		smi_common2: smi@1400e000 {
			compatible = "mediatek,mt8195-smi-common";
			mediatek,common-id = <2>;
			reg = <0 0x1400e000 0 0x1000>;
			clocks = <&vppsys0 CLK_VPP0_SMI_COMMON>,
				 <&vppsys0 CLK_VPP0_SMI_COMMON>,
				 <&vppsys0 CLK_VPP0_GALS_INFRA>,
				 <&vppsys0 CLK_VPP0_GALS_CAMSYS>;
			clock-names = "apb", "smi", "gals0", "gals1";
			power-domains = <&spm MT8195_POWER_DOMAIN_VPPSYS0>;
		};

		smi_common1: smi@14012000 {
			compatible = "mediatek,mt8195-smi-common";
			mediatek,common-id = <1>;
			reg = <0 0x14012000 0 0x1000>;
			clocks = <&vppsys0 CLK_VPP0_SMI_COMMON_LARB4>,
				 <&vppsys0 CLK_VPP0_SMI_COMMON_LARB4>,
				 <&vppsys0 CLK_VPP0_GALS_EMI0_EMI1>,
				 <&vppsys0 CLK_VPP0_SMI_SUB_COMMON_REORDER>;
			clock-names = "apb", "smi", "gals0", "gals1";
			power-domains = <&spm MT8195_POWER_DOMAIN_VPPSYS0>;
		};

		larb4: larb@14013000 {
			compatible = "mediatek,mt8195-smi-larb";
			reg = <0 0x14013000 0 0x1000>;
			mediatek,larb-id = <4>;
			mediatek,smi = <&smi_common1>;
			clocks = <&vppsys0 CLK_VPP0_GALS_VPP1_WPE>,
				 <&vppsys0 CLK_VPP0_SMI_COMMON_LARB4>;
			clock-names = "apb", "smi";
			power-domains = <&spm MT8195_POWER_DOMAIN_VPPSYS0>;
		};

		iommu_vpp: iommu@14018000 {
			compatible = "mediatek,mt8195-iommu-vpp";
			reg = <0 0x14018000 0 0x1000>;
			mediatek,larbs = <&larb1 &larb3 &larb4 &larb6 &larb8
					  &larb12 &larb14 &larb16 &larb18
					  &larb20 &larb22 &larb23 &larb26
					  &larb27>;
			interrupts = <GIC_SPI 594 IRQ_TYPE_LEVEL_HIGH 0>;
			clocks = <&vppsys0 CLK_VPP0_SMI_IOMMU>;
			clock-names = "bclk";
			#iommu-cells = <1>;
			power-domains = <&spm MT8195_POWER_DOMAIN_VPPSYS0>;
		};

		wpesys: syscon@14e00000 {
			compatible = "mediatek,mt8195-wpesys", "syscon";
			reg = <0 0x14e00000 0 0x1000>;
			#clock-cells = <1>;
		};

		wpesys_vpp0: syscon@14e02000 {
			compatible = "mediatek,mt8195-wpesys_vpp0", "syscon";
			reg = <0 0x14e02000 0 0x1000>;
			#clock-cells = <1>;
		};

		wpesys_vpp1: syscon@14e03000 {
			compatible = "mediatek,mt8195-wpesys_vpp1", "syscon";
			reg = <0 0x14e03000 0 0x1000>;
			#clock-cells = <1>;
		};

		larb7: larb@14e04000 {
			compatible = "mediatek,mt8195-smi-larb";
			reg = <0 0x14e04000 0 0x1000>;
			mediatek,larb-id = <7>;
			mediatek,smi = <&smi_common0>;
			clocks = <&wpesys CLK_WPE_SMI_LARB7>,
				 <&wpesys CLK_WPE_SMI_LARB7>;
			clock-names = "apb", "smi";
			power-domains = <&spm MT8195_POWER_DOMAIN_WPESYS>;
		};

		larb8: larb@14e05000 {
			compatible = "mediatek,mt8195-smi-larb";
			reg = <0 0x14e05000 0 0x1000>;
			mediatek,larb-id = <8>;
			mediatek,smi = <&smi_common1>;
			clocks = <&wpesys CLK_WPE_SMI_LARB8>,
				 <&wpesys CLK_WPE_SMI_LARB8>,
				 <&vppsys0 CLK_VPP0_GALS_VPP1_WPE>;
			clock-names = "apb", "smi", "gals";
			power-domains = <&spm MT8195_POWER_DOMAIN_WPESYS>;
		};

		vppsys1: syscon@14f00000 {
			compatible = "mediatek,mt8195-vppsys1", "syscon";
			reg = <0 0x14f00000 0 0x1000>;
			#clock-cells = <1>;
		};

		larb5: larb@14f02000 {
			compatible = "mediatek,mt8195-smi-larb";
			reg = <0 0x14f02000 0 0x1000>;
			mediatek,larb-id = <5>;
			mediatek,smi = <&smi_common0>;
			clocks = <&vppsys1 CLK_VPP1_VPPSYS1_LARB>,
				 <&vppsys1 CLK_VPP1_VPPSYS1_GALS>,
				 <&vppsys0 CLK_VPP0_GALS_VPP1_LARB5>;
			clock-names = "apb", "smi", "gals";
			power-domains = <&spm MT8195_POWER_DOMAIN_VPPSYS1>;
		};

		larb6: larb@14f03000 {
			compatible = "mediatek,mt8195-smi-larb";
			reg = <0 0x14f03000 0 0x1000>;
			mediatek,larb-id = <6>;
			mediatek,smi = <&smi_common1>;
			clocks = <&vppsys0 CLK_VPP0_GALS_VPP1_WPE>,
				 <&vppsys1 CLK_VPP1_VPPSYS1_LARB>,
				 <&vppsys1 CLK_VPP1_VPPSYS1_GALS>,
				 <&vppsys0 CLK_VPP0_GALS_VPP1_LARB6>;
			clock-names = "apb", "smi", "gals", "gals1";
			power-domains = <&spm MT8195_POWER_DOMAIN_VPPSYS1>;
		};

		imgsys: syscon@15000000 {
			compatible = "mediatek,mt8195-imgsys", "syscon";
			reg = <0 0x15000000 0 0x1000>;
			#clock-cells = <1>;
		};

		larb9: larb@15001000 {
			compatible = "mediatek,mt8195-smi-larb";
			reg = <0 0x15001000 0 0x1000>;
			mediatek,larb-id = <9>;
			mediatek,smi = <&smi_common0>;
			clocks = <&imgsys CLK_IMG_LARB9>,
				 <&imgsys CLK_IMG_LARB9>,
				 <&imgsys CLK_IMG_GALS>;
			clock-names = "apb", "smi", "gals";
			power-domains = <&spm MT8195_POWER_DOMAIN_IMG>;
		};

		imgsys1_dip_top: syscon@15110000 {
			compatible = "mediatek,mt8195-imgsys1_dip_top", "syscon";
			reg = <0 0x15110000 0 0x1000>;
			#clock-cells = <1>;
		};

		larb10: larb@15120000 {
			compatible = "mediatek,mt8195-smi-larb";
			reg = <0 0x15120000 0 0x1000>;
			mediatek,larb-id = <10>;
			mediatek,smi = <&smi_common0>;
			clocks = <&imgsys CLK_IMG_DIP0>,
				 <&imgsys1_dip_top CLK_IMG1_DIP_TOP_LARB10>,
				 <&imgsys CLK_IMG_LARB9>,
				 <&imgsys CLK_IMG_GALS>;
			clock-names = "apb", "smi", "gals", "gals1";
			power-domains = <&spm MT8195_POWER_DOMAIN_DIP>;
		};

		imgsys1_dip_nr: syscon@15130000 {
			compatible = "mediatek,mt8195-imgsys1_dip_nr", "syscon";
			reg = <0 0x15130000 0 0x1000>;
			#clock-cells = <1>;
		};

		imgsys1_wpe: syscon@15220000 {
			compatible = "mediatek,mt8195-imgsys1_wpe", "syscon";
			reg = <0 0x15220000 0 0x1000>;
			#clock-cells = <1>;
		};

		larb11: larb@15230000 {
			compatible = "mediatek,mt8195-smi-larb";
			reg = <0 0x15230000 0 0x1000>;
			mediatek,larb-id = <11>;
			mediatek,smi = <&smi_common0>;
			clocks = <&imgsys CLK_IMG_WPE0>,
				 <&imgsys1_wpe CLK_IMG1_WPE_LARB11>,
				 <&imgsys CLK_IMG_LARB9>,
				 <&imgsys CLK_IMG_GALS>;
			clock-names = "apb", "smi", "gals", "gals1";
			power-domains = <&spm MT8195_POWER_DOMAIN_DIP>;
		};

		ipesys: syscon@15330000 {
			compatible = "mediatek,mt8195-ipesys", "syscon";
			reg = <0 0x15330000 0 0x1000>;
			#clock-cells = <1>;
		};

		larb12: larb@15340000 {
			compatible = "mediatek,mt8195-smi-larb";
			reg = <0 0x15340000 0 0x1000>;
			mediatek,larb-id = <12>;
			mediatek,smi = <&smi_common1>;
			clocks = <&imgsys CLK_IMG_IPE>,
				 <&ipesys CLK_IPE_SMI_LARB12>,
				 <&imgsys CLK_IMG_GALS>,
				 <&vppsys0 CLK_VPP0_GALS_IMGSYS_CAMSYS>;
			clock-names = "apb", "smi", "gals", "gals1";
			power-domains = <&spm MT8195_POWER_DOMAIN_IPE>;
		};

		camsys: syscon@16000000 {
			compatible = "mediatek,mt8195-camsys", "syscon";
			reg = <0 0x16000000 0 0x1000>;
			#clock-cells = <1>;
		};

		larb13: larb@16001000 {
			compatible = "mediatek,mt8195-smi-larb";
			reg = <0 0x16001000 0 0x1000>;
			mediatek,larb-id = <13>;
			mediatek,smi = <&smi_common0>;
			clocks = <&camsys CLK_CAM_LARB13>,
				 <&camsys CLK_CAM_LARB13>,
				 <&camsys CLK_CAM_CAM2MM0_GALS>;
			clock-names = "apb", "smi", "gals";
			power-domains = <&spm MT8195_POWER_DOMAIN_CAM>;
		};

		larb14: larb@16002000 {
			compatible = "mediatek,mt8195-smi-larb";
			reg = <0 0x16002000 0 0x1000>;
			mediatek,larb-id = <14>;
			mediatek,smi = <&smi_common1>;
			clocks = <&camsys CLK_CAM_LARB14>,
				 <&camsys CLK_CAM_LARB14>,
				 <&camsys CLK_CAM_CAM2MM1_GALS>,
				 <&camsys CLK_CAM_CAM2SYS_GALS>,
				 <&vppsys0 CLK_VPP0_GALS_IMGSYS_CAMSYS>;
			clock-names = "apb", "smi", "gals", "gals1", "gals2";
			power-domains = <&spm MT8195_POWER_DOMAIN_CAM>;
		};

		larb16: larb@16012000 {
			compatible = "mediatek,mt8195-smi-larb";
			reg = <0 0x16012000 0 0x1000>;
			mediatek,larb-id = <16>;
			mediatek,smi = <&smi_common1>;
			clocks = <&camsys CLK_CAM_LARB14>,
				 <&camsys_rawa CLK_CAM_RAWA_LARBX>,
				 <&camsys CLK_CAM_CAM2MM1_GALS>,
				 <&camsys CLK_CAM_CAM2SYS_GALS>,
				 <&vppsys0 CLK_VPP0_GALS_IMGSYS_CAMSYS>;
			clock-names = "apb", "smi", "gals", "gals1", "gals2";
			power-domains = <&spm MT8195_POWER_DOMAIN_CAM_RAWA>;
		};

		larb17: larb@16013000 {
			compatible = "mediatek,mt8195-smi-larb";
			reg = <0 0x16013000 0 0x1000>;
			mediatek,larb-id = <17>;
			mediatek,smi = <&smi_common0>;
			clocks = <&camsys CLK_CAM_LARB13>,
				 <&camsys_yuva CLK_CAM_YUVA_LARBX>,
				 <&camsys CLK_CAM_CAM2MM0_GALS>;
			clock-names = "apb", "smi", "gals";
			power-domains = <&spm MT8195_POWER_DOMAIN_CAM_RAWA>;
		};

		larb27: larb@16014000 {
			compatible = "mediatek,mt8195-smi-larb";
			reg = <0 0x16014000 0 0x1000>;
			mediatek,larb-id = <27>;
			mediatek,smi = <&smi_common1>;
			clocks = <&camsys CLK_CAM_LARB14>,
				 <&camsys_rawb CLK_CAM_RAWB_LARBX>,
				 <&camsys CLK_CAM_CAM2MM1_GALS>,
				 <&camsys CLK_CAM_CAM2SYS_GALS>,
				 <&vppsys0 CLK_VPP0_GALS_IMGSYS_CAMSYS>;
			clock-names = "apb", "smi", "gals", "gals1", "gals2";
			power-domains = <&spm MT8195_POWER_DOMAIN_CAM_RAWB>;
		};

		larb28: larb@16015000 {
			compatible = "mediatek,mt8195-smi-larb";
			reg = <0 0x16015000 0 0x1000>;
			mediatek,larb-id = <28>;
			mediatek,smi = <&smi_common0>;
			clocks = <&camsys CLK_CAM_LARB13>,
				 <&camsys_yuvb CLK_CAM_YUVB_LARBX>,
				 <&camsys CLK_CAM_CAM2MM0_GALS>;
			clock-names = "apb", "smi", "gals";
			power-domains = <&spm MT8195_POWER_DOMAIN_CAM_RAWB>;
		};

		camsys_rawa: syscon@1604f000 {
			compatible = "mediatek,mt8195-camsys_rawa", "syscon";
			reg = <0 0x1604f000 0 0x1000>;
			#clock-cells = <1>;
		};

		camsys_yuva: syscon@1606f000 {
			compatible = "mediatek,mt8195-camsys_yuva", "syscon";
			reg = <0 0x1606f000 0 0x1000>;
			#clock-cells = <1>;
		};

		camsys_rawb: syscon@1608f000 {
			compatible = "mediatek,mt8195-camsys_rawb", "syscon";
			reg = <0 0x1608f000 0 0x1000>;
			#clock-cells = <1>;
		};

		camsys_yuvb: syscon@160af000 {
			compatible = "mediatek,mt8195-camsys_yuvb", "syscon";
			reg = <0 0x160af000 0 0x1000>;
			#clock-cells = <1>;
		};

		camsys_mraw: syscon@16140000 {
			compatible = "mediatek,mt8195-camsys_mraw", "syscon";
			reg = <0 0x16140000 0 0x1000>;
			#clock-cells = <1>;
		};

		larb25: larb@16141000 {
			compatible = "mediatek,mt8195-smi-larb";
			reg = <0 0x16141000 0 0x1000>;
			mediatek,larb-id = <25>;
			mediatek,smi = <&smi_common0>;
			clocks = <&camsys CLK_CAM_LARB13>,
				 <&camsys_mraw CLK_CAM_MRAW_LARBX>,
				 <&camsys CLK_CAM_CAM2MM0_GALS>;
			clock-names = "apb", "smi", "gals";
			power-domains = <&spm MT8195_POWER_DOMAIN_CAM_MRAW>;
		};

		larb26: larb@16142000 {
			compatible = "mediatek,mt8195-smi-larb";
			reg = <0 0x16142000 0 0x1000>;
			mediatek,larb-id = <26>;
			mediatek,smi = <&smi_common1>;
			clocks = <&camsys CLK_CAM_LARB14>,
				<&camsys_mraw CLK_CAM_MRAW_LARBX>,
				<&camsys CLK_CAM_CAM2MM1_GALS>,
				<&vppsys0 CLK_VPP0_GALS_IMGSYS_CAMSYS>;
			clock-names = "apb", "smi", "gals", "gals1";
			power-domains = <&spm MT8195_POWER_DOMAIN_CAM_MRAW>;

		};

		ccusys: syscon@17200000 {
			compatible = "mediatek,mt8195-ccusys", "syscon";
			reg = <0 0x17200000 0 0x1000>;
			#clock-cells = <1>;
		};

		larb18: larb@17201000 {
			compatible = "mediatek,mt8195-smi-larb";
			reg = <0 0x17201000 0 0x1000>;
			mediatek,larb-id = <18>;
			mediatek,smi = <&smi_common1>;
			clocks = <&camsys CLK_CAM_LARB14>,
				 <&ccusys CLK_CCU_LARB18>,
				 <&camsys CLK_CAM_CAM2MM1_GALS>,
				 <&vppsys0 CLK_VPP0_GALS_IMGSYS_CAMSYS>;
			clock-names = "apb", "smi", "gals", "gals1";
			power-domains = <&spm MT8195_POWER_DOMAIN_CAM>;
		};

		vcodec_dec: vcodec_dec@18000000 {
			compatible = "mediatek,mt8195-vcodec-dec";
			reg = <0 0x18000000 0 0x1000>;		/* VDEC_SYS */
			mediatek,scp = <&scp>;
			iommus = <&iommu_vdo M4U_PORT_L21_VDEC_MC_EXT>;
			dma-ranges = <0x1 0x0 0x0 0x40000000 0x0 0xfff00000>;
		};

		vcodec_lat_soc: vcodec_lat_soc@0x18002000 {
			compatible = "mediatek,mtk-vcodec-lat-soc";
			reg = <0 0x18002000 0 0x800>;		/* VDEC_MISC */
			iommus = <&iommu_vpp M4U_PORT_L23_VDEC_UFO_ENC_EXT>,
				<&iommu_vpp M4U_PORT_L23_VDEC_RDMA_EXT>;
			clocks = <&topckgen CLK_TOP_VDEC>,
				<&vdecsys_soc CLK_VDEC_SOC_VDEC>,
				 <&vdecsys_soc CLK_VDEC_SOC_LAT>,
				 <&topckgen CLK_TOP_UNIVPLL_D4>;
			clock-names = "vdec-sel", "vdec-soc-vdec", "vdec-soc-lat", "vdec-top";
				 assigned-clocks = <&topckgen CLK_TOP_VDEC>;
			assigned-clock-parents = <&topckgen CLK_TOP_UNIVPLL_D4>;
			power-domains = <&spm MT8195_POWER_DOMAIN_VDEC0>;
			dma-ranges = <0x1 0x0 0x0 0x40000000 0x0 0xfff00000>;
		};

		vcodec_lat: vcodec_lat@0x18010000 {
			compatible = "mediatek,mtk-vcodec-lat";
			reg = <0 0x18010000 0 0x800>;		/* VDEC_MISC */
			interrupts = <GIC_SPI 708 IRQ_TYPE_LEVEL_HIGH 0>;
			iommus = <&iommu_vdo M4U_PORT_L24_VDEC_LAT0_VLD_EXT>,
				<&iommu_vdo M4U_PORT_L24_VDEC_LAT0_VLD2_EXT>,
				<&iommu_vdo M4U_PORT_L24_VDEC_LAT0_AVC_MC_EXT>,
				<&iommu_vdo M4U_PORT_L24_VDEC_LAT0_PRED_RD_EXT>,
				<&iommu_vdo M4U_PORT_L24_VDEC_LAT0_TILE_EXT>,
				<&iommu_vdo M4U_PORT_L24_VDEC_LAT0_WDMA_EXT>;
			clocks = <&topckgen CLK_TOP_VDEC>,
				 <&vdecsys_soc CLK_VDEC_SOC_VDEC>,
				 <&vdecsys_soc CLK_VDEC_SOC_LAT>,
				 <&topckgen CLK_TOP_UNIVPLL_D4>;
			clock-names = "vdec-sel", "vdec-soc-vdec", "vdec-soc-lat", "vdec-top";
			assigned-clocks = <&topckgen CLK_TOP_VDEC>;
			assigned-clock-parents = <&topckgen CLK_TOP_UNIVPLL_D4>;
			power-domains =  <&spm MT8195_POWER_DOMAIN_VDEC0>;
			dma-ranges = <0x1 0x0 0x0 0x40000000 0x0 0xfff00000>;
		};

		vcodec_core: vcodec_core@0x18025000 {
			compatible = "mediatek,mtk-vcodec-core";
			reg = <0 0x18025000 0 0x1000>;		/* VDEC_CORE_MISC */
			interrupts = <GIC_SPI 707 IRQ_TYPE_LEVEL_HIGH 0>;
			iommus = <&iommu_vdo M4U_PORT_L21_VDEC_MC_EXT>,
				<&iommu_vdo M4U_PORT_L21_VDEC_UFO_EXT>,
				<&iommu_vdo M4U_PORT_L21_VDEC_PP_EXT>,
				<&iommu_vdo M4U_PORT_L21_VDEC_PRED_RD_EXT>,
				<&iommu_vdo M4U_PORT_L21_VDEC_PRED_WR_EXT>,
				<&iommu_vdo M4U_PORT_L21_VDEC_PPWRAP_EXT>,
				<&iommu_vdo M4U_PORT_L21_VDEC_TILE_EXT>,
				<&iommu_vdo M4U_PORT_L21_VDEC_VLD_EXT>,
				<&iommu_vdo M4U_PORT_L21_VDEC_VLD2_EXT>,
				<&iommu_vdo M4U_PORT_L21_VDEC_AVC_MV_EXT>;
			clocks = <&topckgen CLK_TOP_VDEC>,
				 <&vdecsys CLK_VDEC_VDEC>,
				 <&vdecsys CLK_VDEC_LAT>,
				 <&topckgen CLK_TOP_UNIVPLL_D4>;
			clock-names = "vdec-sel", "vdec-soc-vdec", "vdec-soc-lat", "vdec-top";
			assigned-clocks = <&topckgen CLK_TOP_VDEC>;
			assigned-clock-parents = <&topckgen CLK_TOP_UNIVPLL_D4>;
			power-domains = <&spm MT8195_POWER_DOMAIN_VDEC1>;
			dma-ranges = <0x1 0x0 0x0 0x40000000 0x0 0xfff00000>;
		};

		vcodec_core1: vcodec_core1@0x18035000 {
			compatible = "mediatek,mtk-vcodec-core1";
			reg = <0 0x18035000 0 0x1000>;		/* VDEC_CORE1_MISC */
			interrupts = <GIC_SPI 709 IRQ_TYPE_LEVEL_HIGH 0>;
			iommus = <&iommu_vpp M4U_PORT_L22_VDEC_MC_EXT>,
				<&iommu_vpp M4U_PORT_L22_VDEC_UFO_EXT>,
				<&iommu_vpp M4U_PORT_L22_VDEC_PP_EXT>,
				<&iommu_vpp M4U_PORT_L22_VDEC_PRED_RD_EXT>,
				<&iommu_vpp M4U_PORT_L22_VDEC_PRED_WR_EXT>,
				<&iommu_vpp M4U_PORT_L22_VDEC_PPWRAP_EXT>,
				<&iommu_vpp M4U_PORT_L22_VDEC_TILE_EXT>,
				<&iommu_vpp M4U_PORT_L22_VDEC_VLD_EXT>,
				<&iommu_vpp M4U_PORT_L22_VDEC_VLD2_EXT>,
				<&iommu_vpp M4U_PORT_L22_VDEC_AVC_MV_EXT>;
			clocks = <&topckgen CLK_TOP_VDEC>,
				 <&vdecsys CLK_VDEC_CORE1_VDEC>,
				 <&vdecsys CLK_VDEC_CORE1_LAT>,
				 <&topckgen CLK_TOP_UNIVPLL_D4>;
			clock-names = "vdec-sel", "vdec-soc-vdec", "vdec-soc-lat", "vdec-top";
			assigned-clocks = <&topckgen CLK_TOP_VDEC>;
			assigned-clock-parents = <&topckgen CLK_TOP_UNIVPLL_D4>;
			power-domains = <&spm MT8195_POWER_DOMAIN_VDEC2>;
			dma-ranges = <0x1 0x0 0x0 0x40000000 0x0 0xfff00000>;
		};

		larb24: larb@1800d000 {
			compatible = "mediatek,mt8195-smi-larb";
			reg = <0 0x1800d000 0 0x1000>;
			mediatek,larb-id = <24>;
			mediatek,smi = <&smi_common0>;
			clocks = <&vdecsys_soc CLK_VDEC_SOC_LARB1>,
				 <&vdecsys_soc CLK_VDEC_SOC_LARB1>;
			clock-names = "apb", "smi";
			power-domains = <&spm MT8195_POWER_DOMAIN_VDEC0>;
		};

		larb23: larb@1800e000 {
			compatible = "mediatek,mt8195-smi-larb";
			reg = <0 0x1800e000 0 0x1000>;
			mediatek,larb-id = <23>;
			mediatek,smi = <&smi_common1>;
			clocks = <&vppsys0 CLK_VPP0_GALS_VDEC_VDEC_CORE1>,
				 <&vdecsys_soc CLK_VDEC_SOC_LARB1>;
			clock-names = "apb", "smi";
			power-domains = <&spm MT8195_POWER_DOMAIN_VDEC0>;
		};

		vdecsys_soc: syscon@1800f000 {
			compatible = "mediatek,mt8195-vdecsys_soc", "syscon";
			reg = <0 0x1800f000 0 0x1000>;
			#clock-cells = <1>;
		};

		larb21: larb@1802e000 {
			compatible = "mediatek,mt8195-smi-larb";
			reg = <0 0x1802e000 0 0x1000>;
			mediatek,larb-id = <21>;
			mediatek,smi = <&smi_common0>;
			clocks = <&vdecsys CLK_VDEC_LARB1>,
				 <&vdecsys CLK_VDEC_LARB1>;
			clock-names = "apb", "smi";
			power-domains = <&spm MT8195_POWER_DOMAIN_VDEC1>;
		};

		vdecsys: syscon@1802f000 {
			compatible = "mediatek,mt8195-vdecsys", "syscon";
			reg = <0 0x1802f000 0 0x1000>;
			#clock-cells = <1>;
		};

		larb22: larb@1803e000 {
			compatible = "mediatek,mt8195-smi-larb";
			reg = <0 0x1803e000 0 0x1000>;
			mediatek,larb-id = <22>;
			mediatek,smi = <&smi_common1>;
			clocks = <&vppsys0 CLK_VPP0_GALS_VDEC_VDEC_CORE1>,
				 <&vdecsys_core1 CLK_VDEC_CORE1_LARB1>;
			clock-names = "apb", "smi";
			power-domains = <&spm MT8195_POWER_DOMAIN_VDEC2>;
		};

		vdecsys_core1: syscon@1803f000 {
			compatible = "mediatek,mt8195-vdecsys_core1", "syscon";
			reg = <0 0x1803f000 0 0x1000>;
			#clock-cells = <1>;
		};

		iommu_apu0: iommu@19010000 {
			compatible = "mediatek,mt8195-iommu-apu";
			reg = <0 0x19010000 0 0x1000>;
			interrupts = <GIC_SPI 426 IRQ_TYPE_LEVEL_HIGH 0>;
			clocks = <&clk26m>;
			clock-names = "bclk";
			#iommu-cells = <1>;
			/* power-domains = <&apuspm MT8195_POWER_DOMAIN_APUSYS_TOP>; */
			status = "disabled";
		};

		iommu_apu1: iommu@19015000 {
			compatible = "mediatek,mt8195-iommu-apu";
			reg = <0 0x19015000 0 0x1000>;
			interrupts = <GIC_SPI 431 IRQ_TYPE_LEVEL_HIGH 0>;
			clocks = <&clk26m>;
			clock-names = "bclk";
			#iommu-cells = <1>;
			/* power-domains = <&apuspm MT8195_POWER_DOMAIN_APUSYS_TOP>; */
			status = "disabled";
		};

		apusys_pll: syscon@190f3000 {
			compatible = "mediatek,mt8195-apusys_pll", "syscon";
			reg = <0 0x190f3000 0 0x1000>;
			#clock-cells = <1>;
		};

		vencsys: syscon@1a000000 {
			compatible = "mediatek,mt8195-vencsys", "syscon";
			reg = <0 0x1a000000 0 0x1000>;
			#clock-cells = <1>;
		};

		larb19: larb@1a010000 {
			compatible = "mediatek,mt8195-smi-larb";
			reg = <0 0x1a010000 0 0x1000>;
			mediatek,larb-id = <19>;
			mediatek,smi = <&smi_common0>;
			clocks = <&vencsys CLK_VENC_VENC>,
				 <&vencsys CLK_VENC_LARB>,
				 <&vencsys CLK_VENC_GALS>,
				 <&vppsys0 CLK_VPP0_GALS_VENCSYS>;
			clock-names = "apb", "smi", "gals", "gals1";
			power-domains = <&spm MT8195_POWER_DOMAIN_VENC>;
		};

		vencsys_core1: syscon@1b000000 {
			compatible = "mediatek,mt8195-vencsys_core1", "syscon";
			reg = <0 0x1b000000 0 0x1000>;
			#clock-cells = <1>;
		};

		larb20: larb@1b010000 {
			compatible = "mediatek,mt8195-smi-larb";
			reg = <0 0x1b010000 0 0x1000>;
			mediatek,larb-id = <20>;
			mediatek,smi = <&smi_common1>;
			clocks = <&vencsys_core1 CLK_VENC_CORE1_VENC>,
				 <&vencsys_core1 CLK_VENC_CORE1_LARB>,
				 <&vencsys_core1 CLK_VENC_CORE1_GALS>,
				 <&vppsys0 CLK_VPP0_GALS_VDO0_VDO1_VENCSYS_CORE1>,
				 <&vppsys0 CLK_VPP0_GALS_VENCSYS_CORE1>;
			clock-names = "apb", "smi", "gals", "gals1", "gals2";
			power-domains = <&spm MT8195_POWER_DOMAIN_VENC_CORE1>;
		};

		vdosys0: syscon@1c01a000 {
			compatible = "mediatek,mt8195-vdosys0", "syscon";
			reg = <0 0x1c01a000 0 0x1000>;
			#clock-cells = <1>;
		};

		smi_common0: smi@1c01b000 {
			compatible = "mediatek,mt8195-smi-common";
			mediatek,common-id = <0>;
			reg = <0 0x1c01b000 0 0x1000>;
			clocks = <&vdosys0 CLK_VDO0_SMI_COMMON>,
				 <&vdosys0 CLK_VDO0_SMI_COMMON>,
				 <&vdosys0 CLK_VDO0_SMI_EMI>,
				 <&vdosys0 CLK_VDO0_SMI_GALS>;
			clock-names = "apb", "smi", "gals0", "gals1";
			power-domains = <&spm MT8195_POWER_DOMAIN_VDOSYS0>;

		};

		iommu_vdo: iommu@1c01f000 {
			compatible = "mediatek,mt8195-iommu-vdo";
			reg = <0 0x1c01f000 0 0x1000>;
			mediatek,larbs = <&larb0 &larb2 &larb5 &larb7 &larb9
					  &larb10 &larb11 &larb13 &larb17
					  &larb19 &larb21 &larb24 &larb25
					  &larb28>;
			interrupts = <GIC_SPI 669 IRQ_TYPE_LEVEL_HIGH 0>;
			#iommu-cells = <1>;
			clocks = <&vdosys0 CLK_VDO0_SMI_IOMMU>;
			clock-names = "bclk";
			power-domains = <&spm MT8195_POWER_DOMAIN_VDOSYS0>;
		};

		larb0: larb@1c018000 {
			compatible = "mediatek,mt8195-smi-larb";
			reg = <0 0x1c018000 0 0x1000>;
			mediatek,larb-id = <0>;
			mediatek,smi = <&smi_common0>;
			clocks = <&vdosys0 CLK_VDO0_SMI_LARB>,
				 <&vdosys0 CLK_VDO0_SMI_LARB>,
				 <&vppsys0 CLK_VPP0_GALS_VDO0_LARB0>;
			clock-names = "apb", "smi", "gals";
			power-domains = <&spm MT8195_POWER_DOMAIN_VDOSYS0>;
		};

		larb1: larb@1c019000 {
			compatible = "mediatek,mt8195-smi-larb";
			reg = <0 0x1c019000 0 0x1000>;
			mediatek,larb-id = <1>;
			mediatek,smi = <&smi_common1>;
			clocks = <&vdosys0 CLK_VDO0_SMI_LARB>,
				 <&vppsys0 CLK_VPP0_GALS_VDO0_VDO1_VENCSYS_CORE1>,
				 <&vppsys0 CLK_VPP0_GALS_VDO0_LARB1>;
			clock-names = "apb", "smi", "gals";
			power-domains = <&spm MT8195_POWER_DOMAIN_VDOSYS0>;
		};

		vdosys1: syscon@1c100000 {
			compatible = "mediatek,mt8195-vdosys1", "syscon";
			reg = <0 0x1c100000 0 0x1000>;
			#clock-cells = <1>;
		};

		larb2: larb@1c102000 {
			compatible = "mediatek,mt8195-smi-larb";
			reg = <0 0x1c102000 0 0x1000>;
			mediatek,larb-id = <2>;
			mediatek,smi = <&smi_common0>;
			clocks = <&vdosys1 CLK_VDO1_SMI_LARB2>,
				 <&vdosys1 CLK_VDO1_SMI_LARB2>,
				 <&vdosys1 CLK_VDO1_GALS>;
			clock-names = "apb", "smi", "gals";
			power-domains = <&spm MT8195_POWER_DOMAIN_VDOSYS1>;
		};

		larb3: larb@1c103000 {
			compatible = "mediatek,mt8195-smi-larb";
			reg = <0 0x1c103000 0 0x1000>;
			mediatek,larb-id = <3>;
			mediatek,smi = <&smi_common1>;
			clocks = <&vdosys1 CLK_VDO1_SMI_LARB3>,
				 <&vdosys1 CLK_VDO1_GALS>,
				 <&vppsys0 CLK_VPP0_GALS_VDO0_VDO1_VENCSYS_CORE1>;
			clock-names = "apb", "smi", "gals";
			power-domains = <&spm MT8195_POWER_DOMAIN_VDOSYS1>;
		};
	};
};
